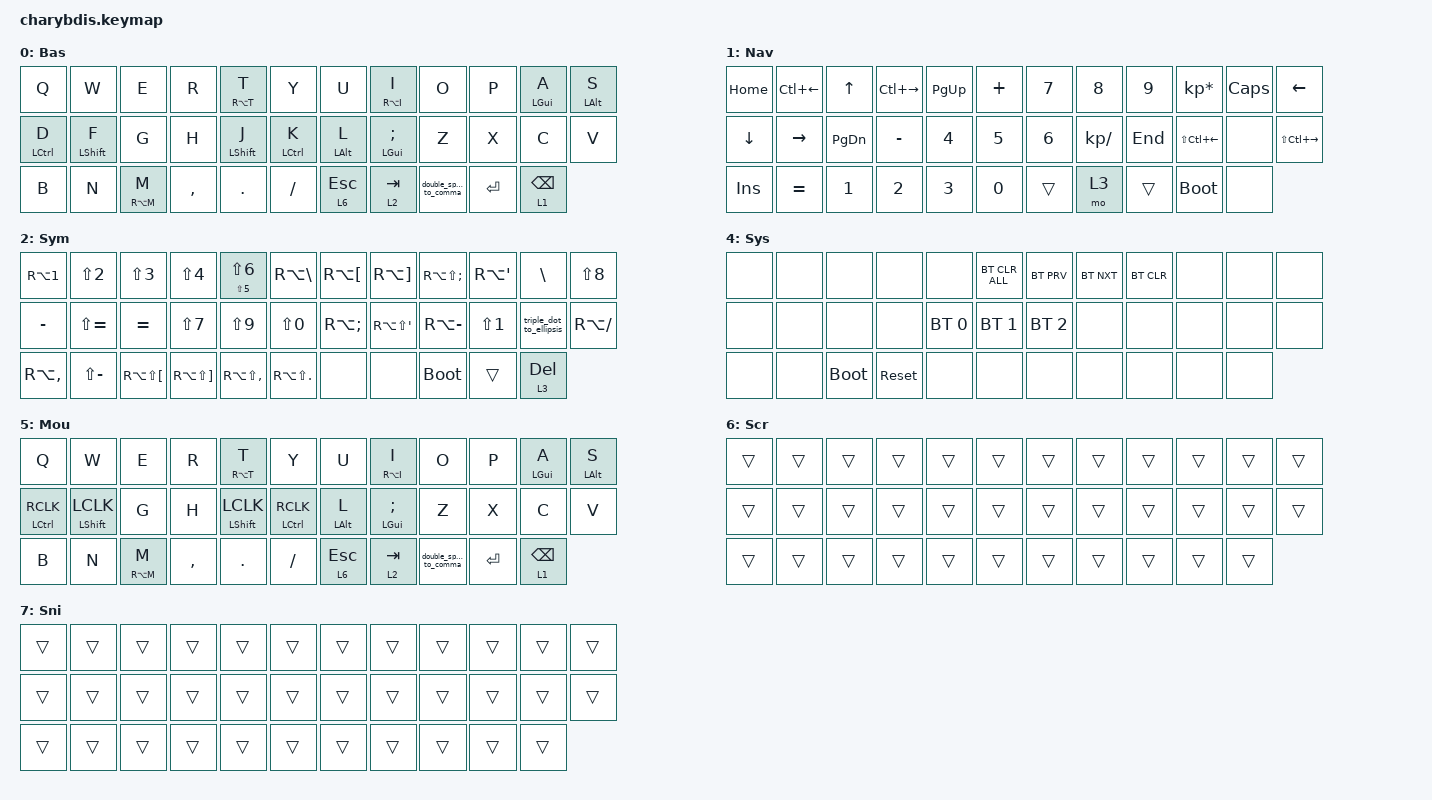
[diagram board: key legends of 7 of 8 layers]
#include <dt-bindings/zmk/mouse.h>
#include <behaviors/mouse_keys.dtsi>
#include <behaviors.dtsi>
#include <dt-bindings/zmk/bt.h>
#include <dt-bindings/zmk/keys.h>
#include <dt-bindings/zmk/outputs.h>

#define BASE 0
#define NAV 1
#define SYM  2
#define FUN  3
#define SYS  4
#define MOU  5
#define SCR  6
#define SNI  7

/ {
    chosen { zmk,matrix_transform = &five_column_transform; };

    macros {
        compatible = "zmk,macros";

        sleep_macro: sleep_macro {
            compatible = "zmk,behavior-macro";
            label = "SLEEP_MACRO";
            #binding-cells = <0>;
            bindings =
                <&kp LG(D) &kp LA(F4) &kp UP_ARROW &kp ENTER>,
                <&macro_wait_time 350>;

            wait-ms = <350>;
        };

        dongle_macro: dongle_macro {
            compatible = "zmk,behavior-macro";
            label = "DONGLE_MACRO";
            #binding-cells = <0>;
            bindings = <&out OUT_USB>;
        };

        bluetooth_macro_1: bluetooth_macro_1 {
            compatible = "zmk,behavior-macro";
            label = "BLUETOOTH_MACRO_1";
            #binding-cells = <0>;
            bindings = <&bt BT_SEL 0 &out OUT_BLE>;
        };

        bluetooth_macro_2: bluetooth_macro_2 {
            compatible = "zmk,behavior-macro";
            label = "BLUETOOTH_MACRO_2";
            #binding-cells = <0>;
            bindings = <&bt BT_SEL 1 &out OUT_BLE>;
        };

        switch_language: switch_language {
            compatible = "zmk,behavior-macro";
            label = "SWITCH_LANGUAGE";
            #binding-cells = <0>;
            bindings = <&kp LS(LEFT_ALT)>;
        };

        greenatom: greenatom {
            compatible = "zmk,behavior-macro";
            label = "GREENATOM";
            #binding-cells = <0>;
            bindings = <&kp LS(G) &kp R &kp E &kp E &kp N &kp A &kp T &kp O &kp M &kp LS(G) &kp R &kp EXCL &kp G &kp O &kp R &kp Y &kp NUMBER_3 &kp ENTER>;
        };

        greenatom_aszi: greenatom_aszi {
            compatible = "zmk,behavior-macro";
            label = "GREENATOM_ASZI";
            #binding-cells = <0>;
            bindings = <&kp LS(G) &kp LS(A) &kp LS(N) &kp A &kp D &kp O &kp L &kp I &kp N &kp S &kp K &kp Y &kp TAB &greenatom>;
        };

        double_space_to_comma_macro: doublle_spase_dot {
            compatible = "zmk,behavior-macro";
            #binding-cells = <0>;
            bindings = <&kp RA(COMMA) &kp SPACE>;
            label = "DOUBLLE_SPASE_DOT";
        };
    };

    combos {
        compatible = "zmk,combos";

        changing_the_language {
            bindings = <&switch_language>;
            key-positions = <16 12 13 17>;
            layers = <0>;
        };

        left_click {
            bindings = <&mkp LCLK>;
            key-positions = <13 12>;
            layers = <0 5 6 7>;
        };

        right_click {
            bindings = <&mkp RCLK>;
            key-positions = <11 12>;
            layers = <0 5 6 7>;
            timeout-ms = <30>;
            require-prior-idle-ms = <20>;
        };

        middle_click {
            bindings = <&mkp MCLK>;
            key-positions = <11 12 13>;
            layers = <0 5 6 7>;
        };

        comma_vertical_combo {
            bindings = <&kp RA(COMMA)>;
            key-positions = <3 13>;
        };

        automouse_left_middle_click {
            bindings = <&mkp MCLK>;
            key-positions = <11 12>;
            layers = <5>;
        };

        automouse_right_middle_click {
            bindings = <&mkp MCLK>;
            key-positions = <15 16>;
            layers = <5>;
        };
    };

    behaviors {
        ht: ht {
            compatible = "zmk,behavior-hold-tap";
            label = "HT";
            bindings = <&kp>, <&kp>;

            #binding-cells = <2>;
            tapping-term-ms = <300>;
            quick-tap-ms = <300>;
            require-prior-idle-ms = <100>;
            flavor = "tap-preferred";
        };

        ht_greenatom: ht_greenatom {
            compatible = "zmk,behavior-hold-tap";
            label = "HT_GREENATOM";
            bindings = <&greenatom>, <&bluetooth_macro_1>;

            #binding-cells = <2>;
            flavor = "tap-preferred";
            tapping-term-ms = <300>;
            quick-tap-ms = <300>;
            require-prior-idle-ms = <100>;
        };

        ht_greenatom_aszi: ht_greenatom_aszi {
            compatible = "zmk,behavior-hold-tap";
            label = "HT_GREENATOM_ASZI";
            bindings = <&greenatom_aszi>, <&dongle_macro>;

            #binding-cells = <2>;
            flavor = "tap-preferred";
            tapping-term-ms = <300>;
            quick-tap-ms = <300>;
            require-prior-idle-ms = <100>;
        };

        triple_dot_to_ellipsis: triple_dot_to_ellipsis {
            compatible = "zmk,behavior-tap-dance";
            label = "TRIPLE_DOT_TO_ELLIPSIS";
            #binding-cells = <0>;
            bindings = <&kp RA(PERIOD)>, <&none>, <&kp RA(NUMBER_2)>;
        };

        double_space_to_comma: double_space_to_comma {
            compatible = "zmk,behavior-tap-dance";
            label = "DOUBLE_SPACE_TO_COMMA";
            #binding-cells = <0>;
            bindings = <&kp SPACE>, <&double_space_to_comma_macro>;

            tapping-term-ms = <400>;
        };

        automouse_clics: automouse_clics {
            compatible = "zmk,behavior-hold-tap";
            label = "AUTOMOUSE_CLICS";
            bindings = <&kp>, <&mkp>;

            #binding-cells = <2>;
            flavor = "balanced";
            tapping-term-ms = <200>;
        };
    };

    keymap {
        compatible = "zmk,keymap";

        Base {
            label = "Bas";
            bindings = <
&kp Q        &kp W        &kp E        &kp R      &ht RA(T) T  &kp Y          &kp U         &ht RA(I) I         &kp O                   &kp P      &ht LGUI A       &ht LALT S
&ht LCTRL D  &ht LSHFT F  &kp G        &kp H      &ht LSHFT J  &ht LCTRL K    &ht LALT L    &ht LGUI SEMICOLON  &kp Z                   &kp X      &kp C            &kp V
&kp B        &kp N        &ht RA(M) M  &kp COMMA  &kp DOT      &kp SLASH      &lt 6 ESCAPE  &lt 2 TAB           &double_space_to_comma  &kp ENTER  &lt 1 BACKSPACE
            >;
        };

        Navigation {
            label = "Nav";
            bindings = <
&kp HOME        &kp LC(LEFT)     &kp UP_ARROW   &kp LC(RIGHT)  &kp PAGE_UP   &kp PLUS        &kp NUMBER_7  &kp NUMBER_8   &kp NUMBER_9  &kp KP_MULTIPLY   &kp CAPSLOCK  &kp LEFT_ARROW
&kp DOWN_ARROW  &kp RIGHT_ARROW  &kp PAGE_DOWN  &kp MINUS      &kp NUMBER_4  &kp NUMBER_5    &kp NUMBER_6  &kp KP_DIVIDE  &kp END       &kp LS(LC(LEFT))  &none         &kp LS(LC(RIGHT))
&kp INSERT      &kp EQUAL        &kp NUMBER_1   &kp NUMBER_2   &kp NUMBER_3  &kp NUMBER_0    &trans        &mo 3          &trans        &bootloader       &none
            >;
        };

        Symbol {
            label = "Sym";
            bindings = <
&kp RA(NUMBER_1)  &kp LS(NUMBER_2)  &kp LS(NUMBER_3)          &kp LS(NUMBER_4)           &ht LS(N5) LS(NUMBER_6)  &kp RA(BACKSLASH)     &kp RA(LEFT_BRACKET)  &kp RA(RIGHT_BRACKET)   &kp RA(LS(SEMICOLON))  &kp RA(SINGLE_QUOTE)  &kp BACKSLASH            &kp LS(NUMBER_8)
&kp MINUS         &kp LS(EQUAL)     &kp EQUAL                 &kp LS(NUMBER_7)           &kp LS(NUMBER_9)         &kp LS(NUMBER_0)      &kp RA(SEMICOLON)     &kp RA(LS(APOSTROPHE))  &kp RA(MINUS)          &kp LS(NUMBER_1)      &triple_dot_to_ellipsis  &kp RA(SLASH)
&kp RA(COMMA)     &kp LS(MINUS)     &kp RA(LS(LEFT_BRACKET))  &kp RA(LS(RIGHT_BRACKET))  &kp RA(LS(COMMA))        &kp RA(LS(PERIOD))    &none                 &none                   &bootloader            &trans                &lt 3 DELETE
            >;
        };

        Function {
            label = "Fnc";
            bindings = <
&kp F1  &kp F2      &kp F3                &kp F4              &kp C_BRIGHTNESS_INC    &kp C_VOLUME_UP    &kp C_PREVIOUS  &kp C_PLAY_PAUSE  &kp C_NEXT  &kp PRINTSCREEN  &kp F5   &kp F6
&kp F7  &kp F8      &kp C_BRIGHTNESS_DEC  &kp C_VOLUME_DOWN   &kp LEFT_SHIFT          &kp LCTRL          &kp LEFT_ALT    &kp LEFT_WIN      &kp F9      &kp F10          &kp F11  &kp F12
&mo 4   &kp C_MUTE  &ht_greenatom 0 0     &bluetooth_macro_2  &ht_greenatom_aszi 0 0  &none              &none           &none             &none       &none
            >;
        };

        System {
            label = "Sys";
            bindings = <
&none  &none  &none        &none       &none         &bt BT_CLR_ALL    &bt BT_PRV    &bt BT_NXT  &bt BT_CLR  &none  &none  &none
&none  &none  &none        &none       &bt BT_SEL 0  &bt BT_SEL 1      &bt BT_SEL 2  &none       &none       &none  &none  &none
&none  &none  &bootloader  &sys_reset  &none         &none             &none         &none       &none       &none  &none
            >;
        };

        Mouse {
            label = "Mou";
            bindings = <
&kp Q                        &kp W                             &kp E        &kp R      &ht RA(T) T                       &kp Y                          &kp U         &ht RA(I) I         &kp O                   &kp P      &ht LGUI A       &ht LALT S
&automouse_clics LCTRL RCLK  &automouse_clics LEFT_SHIFT LCLK  &kp G        &kp H      &automouse_clics LEFT_SHIFT LCLK  &automouse_clics LCTRL RCLK    &ht LALT L    &ht LGUI SEMICOLON  &kp Z                   &kp X      &kp C            &kp V
&kp B                        &kp N                             &ht RA(M) M  &kp COMMA  &kp DOT                           &kp SLASH                      &lt 6 ESCAPE  &lt 2 TAB           &double_space_to_comma  &kp ENTER  &lt 1 BACKSPACE
            >;
        };

        Scroll {
            label = "Scr";
            bindings = <
&trans  &trans  &trans  &trans  &trans  &trans    &trans  &trans  &trans  &trans  &trans  &trans
&trans  &trans  &trans  &trans  &trans  &trans    &trans  &trans  &trans  &trans  &trans  &trans
&trans  &trans  &trans  &trans  &trans  &trans    &trans  &trans  &trans  &trans  &trans
            >;
        };

        Sniper {
            label = "Sni";
            bindings = <
&trans  &trans  &trans  &trans  &trans  &trans    &trans  &trans  &trans  &trans  &trans  &trans
&trans  &trans  &trans  &trans  &trans  &trans    &trans  &trans  &trans  &trans  &trans  &trans
&trans  &trans  &trans  &trans  &trans  &trans    &trans  &trans  &trans  &trans  &trans
            >;
        };
    };
};

/* mouse move/scroll tuning */

&mmv {
    x-input-code = <INPUT_REL_X>;
    y-input-code = <INPUT_REL_Y>;
    time-to-max-speed-ms = <300>;
    acceleration-exponent = <3>;
};

&msc {
    x-input-code = <INPUT_REL_HWHEEL>;
    y-input-code = <INPUT_REL_WHEEL>;
    time-to-max-speed-ms = <1>;
    acceleration-exponent = <3>;
};
